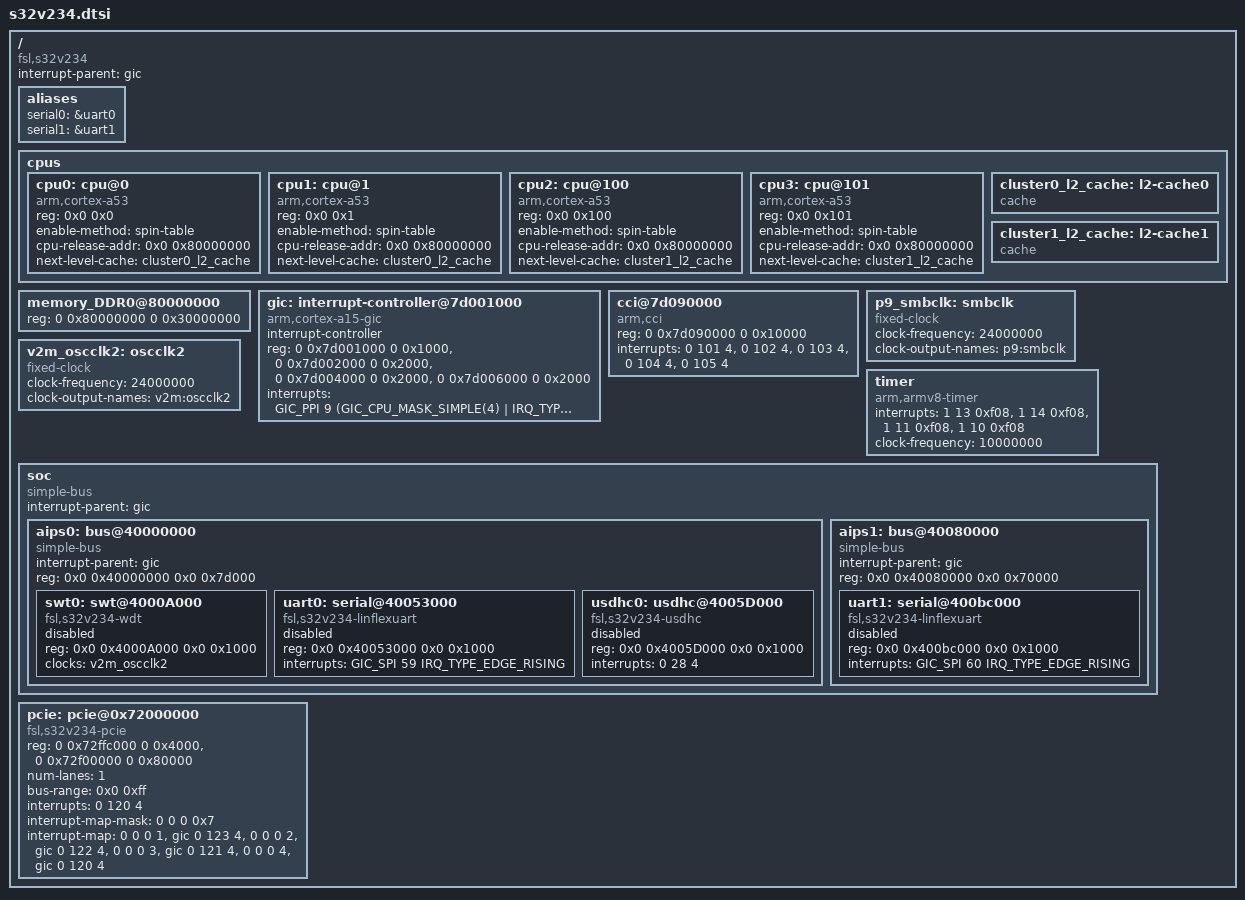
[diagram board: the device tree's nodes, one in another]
// SPDX-License-Identifier: GPL-2.0-or-later
/*
 * Copyright 2015-2016 Freescale Semiconductor, Inc.
 * Copyright 2016-2018 NXP
 */

#include <dt-bindings/interrupt-controller/arm-gic.h>

/memreserve/ 0x80000000 0x00010000;

/ {
	compatible = "fsl,s32v234";
	interrupt-parent = <&gic>;
	#address-cells = <2>;
	#size-cells = <2>;

	aliases {
		serial0 = &uart0;
		serial1 = &uart1;
	};

	cpus {
		#address-cells = <2>;
		#size-cells = <0>;

		cpu0: cpu@0 {
			device_type = "cpu";
			compatible = "arm,cortex-a53";
			reg = <0x0 0x0>;
			enable-method = "spin-table";
			cpu-release-addr = <0x0 0x80000000>;
			next-level-cache = <&cluster0_l2_cache>;
		};

		cpu1: cpu@1 {
			device_type = "cpu";
			compatible = "arm,cortex-a53";
			reg = <0x0 0x1>;
			enable-method = "spin-table";
			cpu-release-addr = <0x0 0x80000000>;
			next-level-cache = <&cluster0_l2_cache>;
		};

		cpu2: cpu@100 {
			device_type = "cpu";
			compatible = "arm,cortex-a53";
			reg = <0x0 0x100>;
			enable-method = "spin-table";
			cpu-release-addr = <0x0 0x80000000>;
			next-level-cache = <&cluster1_l2_cache>;
		};

		cpu3: cpu@101 {
			device_type = "cpu";
			compatible = "arm,cortex-a53";
			reg = <0x0 0x101>;
			enable-method = "spin-table";
			cpu-release-addr = <0x0 0x80000000>;
			next-level-cache = <&cluster1_l2_cache>;
		};

		cluster0_l2_cache: l2-cache0 {
			compatible = "cache";
		};

		cluster1_l2_cache: l2-cache1 {
			compatible = "cache";
		};
	};

	memory_DDR0@80000000 {
		device_type = "memory";
		reg = <0 0x80000000 0 0x30000000>;
	};
/*
	memory_DDR1@c0000000 {
		device_type = "memory";
		reg = <0 0xc0000000 0 0x40000000>;
	};
*/

	gic: interrupt-controller@7d001000 {
		compatible = "arm,cortex-a15-gic", "arm,cortex-a9-gic";
		#interrupt-cells = <3>;
		#address-cells = <0>;
		interrupt-controller;
		reg = <0 0x7d001000 0 0x1000>,
		      <0 0x7d002000 0 0x2000>,
		      <0 0x7d004000 0 0x2000>,
		      <0 0x7d006000 0 0x2000>;
		interrupts = <GIC_PPI 9 (GIC_CPU_MASK_SIMPLE(4) |
					 IRQ_TYPE_LEVEL_HIGH)>;
	};

	cci@7d090000 {
		compatible = "arm,cci";
		reg = <0 0x7d090000 0 0x10000>;
		interrupts = <0 101 4>,
			     <0 102 4>,
			     <0 103 4>,
			     <0 104 4>,
			     <0 105 4>;
	};

	p9_smbclk: smbclk {
		/* Static memory controller clock */
		compatible = "fixed-clock";
		#clock-cells = <0>;
		clock-frequency = <24000000>;
		clock-output-names = "p9:smbclk";
	};

	v2m_oscclk2: oscclk2 {
		/* IO FPGA peripheral clock */
		compatible = "fixed-clock";
		#clock-cells = <0>;
		clock-frequency = <24000000>;
		clock-output-names = "v2m:oscclk2";
	};

	timer {
		compatible = "arm,armv8-timer";
		interrupts = <1 13 0xf08>,
			     <1 14 0xf08>,
			     <1 11 0xf08>,
			     <1 10 0xf08>;
		/* clock-frequency might be modified by u-boot, depending on the
		 * chip version.
		 */
		clock-frequency = <10000000>;
	};

	soc {
		#address-cells = <2>;
		#size-cells = <2>;
		compatible = "simple-bus";
		interrupt-parent = <&gic>;
		ranges;

		aips0: bus@40000000 {
			compatible = "simple-bus";
			#address-cells = <2>;
			#size-cells = <2>;
			interrupt-parent = <&gic>;
			reg = <0x0 0x40000000 0x0 0x7d000>;
			ranges;

			swt0:swt@4000A000 {
				compatible = "fsl,s32v234-wdt", "fsl,sac58r-wdt";
				reg = <0x0 0x4000A000 0x0 0x1000>;
				clocks = <&v2m_oscclk2>;
				clock-names = "swt";
				status = "disabled";
			};

			uart0: serial@40053000 {
				compatible = "fsl,s32v234-linflexuart";
				reg = <0x0 0x40053000 0x0 0x1000>;
				interrupts = <GIC_SPI 59 IRQ_TYPE_EDGE_RISING>;
				status = "disabled";
			};

			usdhc0: usdhc@4005D000 {
				compatible = "fsl,s32v234-usdhc", "fsl,sac85r-usdhc";
				reg = <0x0 0x4005D000 0x0 0x1000>;
				interrupts = <0 28 4>;
				/* Uncomment the bellow definition after clocks
				 * framework is updated */
				/* clocks = <&clks S32V234_CLK_SYS6>,
						<&clks S32V234_CLK_SYS6>,
						<&clks S32V234_CLK_SDHC>; */
				clock-names = "ipg", "ahb", "per";
				status = "disabled";
			};
		};

		aips1: bus@40080000 {
			compatible = "simple-bus";
			#address-cells = <2>;
			#size-cells = <2>;
			interrupt-parent = <&gic>;
			reg = <0x0 0x40080000 0x0 0x70000>;
			ranges;

			uart1: serial@400bc000 {
				compatible = "fsl,s32v234-linflexuart";
				reg = <0x0 0x400bc000 0x0 0x1000>;
				interrupts = <GIC_SPI 60 IRQ_TYPE_EDGE_RISING>;
				status = "disabled";
			};
		};
	};

	pcie: pcie@0x72000000 {
		compatible = "fsl,s32v234-pcie";
		reg = <0 0x72ffc000 0 0x4000>, <0 0x72f00000 0 0x80000>;
		reg-names = "dbi", "config";
		#address-cells = <3>;
		#size-cells = <2>;
		device_type = "pci";
		ranges = <0x81000000 0 0          0 0x72f80000 0 0x00010000 /* downstream I/O */
			  0x82000000 0 0x72000000 0 0x72000000 0 0x00f00000>; /* non-prefetchable memory */
		num-lanes = <1>;
		bus-range = <0x0 0xff>;
		interrupts = <0 120 4>;
		interrupt-names = "msi";
		#interrupt-cells = <1>;
		interrupt-map-mask = <0 0 0 0x7>;
		interrupt-map = <0 0 0 1 &gic 0 123 4>,	<0 0 0 2 &gic 0 122 4>,	<0 0 0 3 &gic 0 121 4>,	<0 0 0 4 &gic 0 120 4>;
		status = "okay";
	};
};
